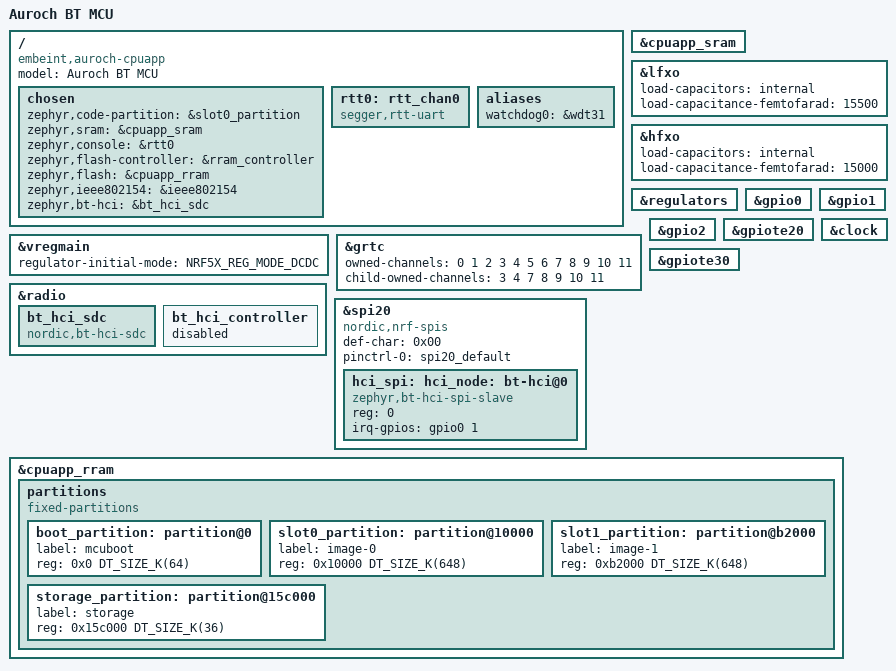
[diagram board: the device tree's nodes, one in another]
/*
 * Copyright (c) 2025 Embeint Holdings Pty Ltd
 *
 * SPDX-License-Identifier: Apache-2.0
 */

/dts-v1/;
#include <nordic/nrf54l15_cpuapp.dtsi>
#include "auroch_nrf54l15_cpuapp-pinctrl.dtsi"

/ {
	model = "Auroch BT MCU";
	compatible = "embeint,auroch-cpuapp";

	chosen {
		zephyr,code-partition = &slot0_partition;
		zephyr,sram = &cpuapp_sram;
		zephyr,console = &rtt0;
		zephyr,flash-controller = &rram_controller;
		zephyr,flash = &cpuapp_rram;
		zephyr,ieee802154 = &ieee802154;
		zephyr,bt-hci = &bt_hci_sdc;
	};

	rtt0: rtt_chan0 {
		compatible = "segger,rtt-uart";
		status = "okay";
	};

	aliases {
		watchdog0 = &wdt31;
	};
};

&cpuapp_sram {
	status = "okay";
};

&lfxo {
	load-capacitors = "internal";
	load-capacitance-femtofarad = <15500>;
};

&hfxo {
	load-capacitors = "internal";
	load-capacitance-femtofarad = <15000>;
};

&regulators {
	status = "okay";
};

&vregmain {
	status = "okay";
	regulator-initial-mode = <NRF5X_REG_MODE_DCDC>;
};

&grtc {
	owned-channels = <0 1 2 3 4 5 6 7 8 9 10 11>;
	/* Channels 7-11 reserved for Zero Latency IRQs, 3-4 for FLPR */
	child-owned-channels = <3 4 7 8 9 10 11>;
	status = "okay";
};

&gpio0 {
	status = "okay";
};

&gpio1 {
	status = "okay";
};

&gpio2 {
	status = "okay";
};

&gpiote20 {
	status = "okay";
};

&gpiote30 {
	status = "okay";
};

&radio {
	status = "okay";
};

&clock {
	status = "okay";
};

&spi20 {
	compatible = "nordic,nrf-spis";
	status = "okay";
	def-char = <0x00>;
	pinctrl-0 = <&spi20_default>;
	pinctrl-names = "default";
	/delete-property/rx-delay-supported;
	/delete-property/rx-delay;

	hci_spi: hci_node: bt-hci@0 {
		compatible = "zephyr,bt-hci-spi-slave";
		reg = <0>;
		irq-gpios = <&gpio0 1 GPIO_ACTIVE_HIGH>;
		/* Additional GPIO is available here:
		 * extra-gpios = <&gpio0 0 0>;
		 */
	};
};

&radio {
	bt_hci_sdc: bt_hci_sdc {
		compatible = "nordic,bt-hci-sdc";
		status = "okay";
	};
	bt_hci_controller {
		status = "disabled";
	};
};

&cpuapp_rram {
	partitions {
		compatible = "fixed-partitions";
		#address-cells = <1>;
		#size-cells = <1>;
		boot_partition: partition@0 {
			label = "mcuboot";
			reg = <0x0 DT_SIZE_K(64)>;
		};
		slot0_partition: partition@10000 {
			label = "image-0";
			reg = <0x10000 DT_SIZE_K(648)>;
		};
		slot1_partition: partition@b2000 {
			label = "image-1";
			reg = <0xb2000 DT_SIZE_K(648)>;
		};
		/* 32k from 0x154000 to 0x15bfff reserved for TF-M partitions */
		storage_partition: partition@15c000 {
			label = "storage";
			reg = <0x15c000 DT_SIZE_K(36)>;
		};
	};
};
